AUTOSAR XML (schema 00049)
package /Components
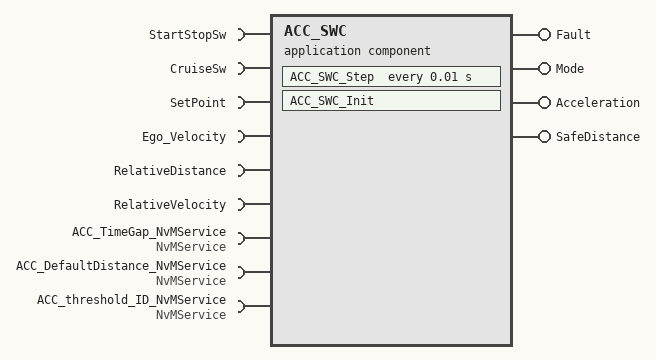
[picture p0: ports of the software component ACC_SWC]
  application sw component type ACC_SWC
    6 x require port:
      StartStopSw: nonqueued-receiver-com-spec{data-element=StartStopSw, init-value=0}, required-interface=StartStopSw
      CruiseSw: nonqueued-receiver-com-spec{data-element=CruiseSw, init-value=0}, required-interface=CruiseSw
      SetPoint: nonqueued-receiver-com-spec{data-element=SetPoint, init-value=0}, required-interface=SetPoint
      Ego_Velocity: nonqueued-receiver-com-spec{data-element=Ego_Velocity, init-value=0}, required-interface=Ego_Velocity
      RelativeDistance: nonqueued-receiver-com-spec{data-element=RelativeDistance, init-value=0}, required-interface=RelativeDistance
      RelativeVelocity: nonqueued-receiver-com-spec{data-element=RelativeVelocity, init-value=0}, required-interface=RelativeVelocity
    4 x provide port:
      Fault: nonqueued-sender-com-spec{data-element=Fault, init-value=0}, provided-interface=Fault
      Mode: nonqueued-sender-com-spec{data-element=Mode, init-value=Accelerate}, provided-interface=Mode
      Acceleration: nonqueued-sender-com-spec{data-element=Acceleration, init-value=0}, provided-interface=Acceleration
      SafeDistance: nonqueued-sender-com-spec{data-element=SafeDistance, init-value=0}, provided-interface=SafeDistance
    require port ACC_TimeGap_NvMService: required-interface=NvMService
    require port ACC_DefaultDistance_NvMService: required-interface=NvMService
    require port ACC_threshold_ID_NvMService: required-interface=NvMService
    behavior ACC_SWC_IB: handle-termination-and-restart=NO-SUPPORT
      timing event Event_ACC_SWC_Step: start-on-event=ACC_SWC_Step, period=0.01
      runnable ACC_SWC_Init
        async call SC_ACC_DefaultDistance_NvMService_ReadBlock: operation=ACC_DefaultDistance_NvMService.ReadBlock, timeout=1
        async call SC_ACC_TimeGap_NvMService_ReadBlock: operation=ACC_TimeGap_NvMService.ReadBlock, timeout=1
        async call SC_ACC_threshold_ID_NvMService_ReadBlock: operation=ACC_threshold_ID_NvMService.ReadBlock, timeout=1
      runnable ACC_SWC_Step
        data-read-access:
          6 x access:
            IN_CruiseSw_CruiseSw: accessed-variable=CruiseSw.CruiseSw
            IN_Ego_Velocity_Ego_Velocity: accessed-variable=Ego_Velocity.Ego_Velocity
            IN_RelativeDistance_RelativeDistance: accessed-variable=RelativeDistance.RelativeDistance
            IN_RelativeVelocity_RelativeVelocity: accessed-variable=RelativeVelocity.RelativeVelocity
            IN_SetPoint_SetPoint: accessed-variable=SetPoint.SetPoint
            IN_StartStopSw_StartStopSw: accessed-variable=StartStopSw.StartStopSw
        data-write-access:
          4 x access:
            OUT_Fault_Fault: accessed-variable=Fault.Fault
            OUT_Mode_Mode: accessed-variable=Mode.Mode
            OUT_Acceleration_Acceleration: accessed-variable=Acceleration.Acceleration
            OUT_SafeDistance_SafeDistance: accessed-variable=SafeDistance.SafeDistance
